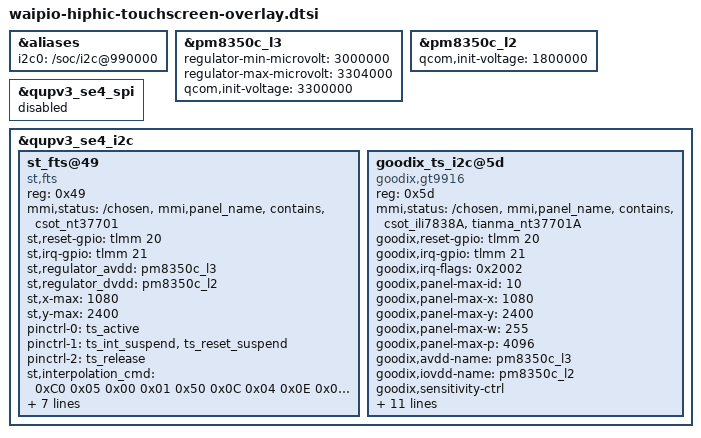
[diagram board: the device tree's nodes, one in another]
/*
 * Copyright (c) 2019, The Linux Foundation. All rights reserved.
 *
 * This program is free software; you can redistribute it and/or modify
 * it under the terms of the GNU General Public License version 2 and
 * only version 2 as published by the Free Software Foundation.
 *
 * This program is distributed in the hope that it will be useful,
 * but WITHOUT ANY WARRANTY; without even the implied warranty of
 * MERCHANTABILITY or FITNESS FOR A PARTICULAR PURPOSE.  See the
 * GNU General Public License for more details.
 */
#include <dt-bindings/clock/qcom,rpmh.h>

&aliases {
	i2c0 = "/soc/i2c@990000";
};

&pm8350c_l3 {
	regulator-min-microvolt = <3000000>;
	regulator-max-microvolt = <3304000>;
	qcom,init-voltage = <3300000>;
};

&pm8350c_l2 {
	qcom,init-voltage = <1800000>;
};

&qupv3_se4_spi {
	status = "disabled";
};

&qupv3_se4_i2c {
	#address-cells = <1>;
	#size-cells = <0>;

	status = "ok";

	st_fts@49 {
		status = "ok";
		compatible = "st,fts";
		reg = <0x49>;
		mmi,status = "/chosen","mmi,panel_name","contains","csot_nt37701";
		st,reset-gpio = <&tlmm 20 0>;
		st,irq-gpio = <&tlmm 21 0x2008>;
		st,regulator_avdd = "pm8350c_l3";
		st,regulator_dvdd = "pm8350c_l2";
		st,x-max = <1080>;
		st,y-max = <2400>;
		pinctrl-names = "pmx_ts_active", "pmx_ts_suspend", "pmx_ts_release";
		pinctrl-0 = <&ts_active>;
		pinctrl-1 = <&ts_int_suspend &ts_reset_suspend>;
		pinctrl-2 = <&ts_release>;
		/* support report rate interpolation */
		st,interpolation_cmd = /bits/ 8 <0xC0 0x05 0x00 0x01 0x50 0x0C 0x04 0x0E 0x01 0x10>;
		/* support report rate switching */
		st,report_rate_cmd = /bits/ 8 <0xC0 0x1C 0x00>;
		/* support edge suppression switching */
		st,edge_cmd = /bits/ 8 <0xC0 0x1F 0x00 0x00>;
		/* support film sensitivity switching */
		st,sensitivity_cmd = /bits/ 8 <0xC0 0x20 0x00>;
		mmi,enable-gestures;
		mmi,power-off-suspend;
		mmi,usb-charger-detection;
		mmi,refresh-rate-update;
	};

	goodix_ts_i2c@5d {
		status = "ok";
		compatible = "goodix,gt9916";
		reg = <0x5d>;
		mmi,status = "/chosen","mmi,panel_name","contains","csot_ili7838A","tianma_nt37701A";
		goodix,reset-gpio = <&tlmm 20 0x0>;
		goodix,irq-gpio = <&tlmm 21 0x2002>;
		goodix,irq-flags = <0x2002>; /* 1:trigger rising, 2:trigger falling;*/
		goodix,panel-max-id = <10>;
		goodix,panel-max-x = <1080>;
		goodix,panel-max-y = <2400>;
		goodix,panel-max-w = <255>;
		goodix,panel-max-p = <4096>;
		goodix,avdd-name = "pm8350c_l3";
		goodix,iovdd-name = "pm8350c_l2";
		goodix,sensitivity-ctrl;
		goodix,film_mode-ctrl;
		goodix,report_rate-ctrl;
		goodix,interpolation-ctrl;
		goodix,edge-ctrl;
		pinctrl-names = "pmx_ts_active", "pmx_ts_suspend", "pmx_ts_release";
		pinctrl-0 = <&ts_active>;
		pinctrl-1 = <&ts_int_suspend &ts_reset_suspend>;
		pinctrl-2 = <&ts_release>;
		mmi,enable-gestures;
		mmi,power-off-suspend;
		mmi,usb-charger-detection;
		mmi,refresh-rate-update;
	};
};
